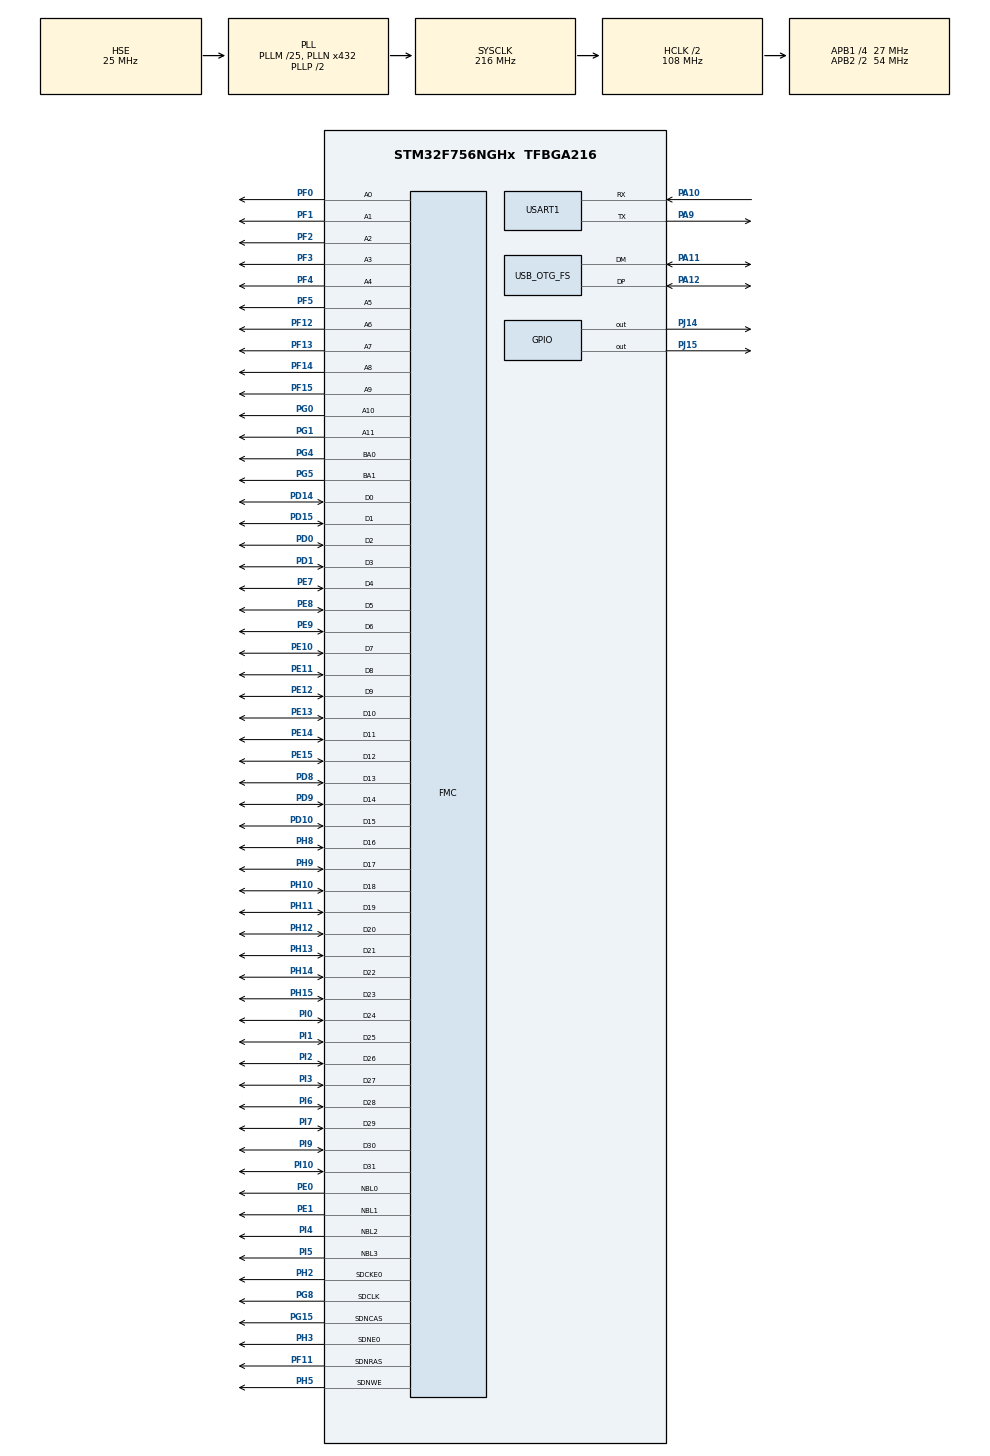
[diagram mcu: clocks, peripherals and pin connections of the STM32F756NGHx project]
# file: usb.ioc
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FMC.CASLatency1=FMC_SDRAM_CAS_LATENCY_3
FMC.ExitSelfRefreshDelay1=10
FMC.LoadToActiveDelay1=2
FMC.RCDDelay1=3
FMC.RPDelay1=3
FMC.RPDelay2=3
FMC.ReadBurst1=FMC_SDRAM_RBURST_ENABLE
FMC.ReadBurst2=FMC_SDRAM_RBURST_ENABLE
FMC.RowBitsNumber1=FMC_SDRAM_ROW_BITS_NUM_12
FMC.RowCycleDelay1=8
FMC.RowCycleDelay2=8
FMC.SDClockPeriod1=FMC_SDRAM_CLOCK_PERIOD_2
FMC.SDClockPeriod2=FMC_SDRAM_CLOCK_PERIOD_2
FMC.SelfRefreshTime1=4
FMC.WriteRecoveryTime1=2
Mcu.Family=STM32F7
Mcu.Name=STM32F756NGHx
Mcu.Package=TFBGA216
NVIC.OTG_FS_IRQn=true\:0\:0\:false\:false\:true
NVIC.PriorityGroup=NVIC_PRIORITYGROUP_4
PA10.Mode=Asynchronous
PA10.Signal=USART1_RX
PA11.Mode=Device_Only
PA11.Signal=USB_OTG_FS_DM
PA12.Mode=Device_Only
PA12.Signal=USB_OTG_FS_DP
PA9.Mode=Asynchronous
PA9.Signal=USART1_TX
PD0.Signal=FMC_D2_DA2
PD1.Signal=FMC_D3_DA3
PD10.Signal=FMC_D15_DA15
PD14.Signal=FMC_D0_DA0
PD15.Signal=FMC_D1_DA1
PD8.Signal=FMC_D13_DA13
PD9.Signal=FMC_D14_DA14
PE0.Signal=FMC_NBL0
PE1.Signal=FMC_NBL1
PE10.Signal=FMC_D7_DA7
PE11.Signal=FMC_D8_DA8
PE12.Signal=FMC_D9_DA9
PE13.Signal=FMC_D10_DA10
PE14.Signal=FMC_D11_DA11
PE15.Signal=FMC_D12_DA12
PE7.Signal=FMC_D4_DA4
PE8.Signal=FMC_D5_DA5
PE9.Signal=FMC_D6_DA6
PF0.Signal=FMC_A0
PF1.Signal=FMC_A1
PF11.Signal=FMC_SDNRAS
PF12.Signal=FMC_A6
PF13.Signal=FMC_A7
PF14.Signal=FMC_A8
PF15.Signal=FMC_A9
PF2.Signal=FMC_A2
PF3.Signal=FMC_A3
PF4.Signal=FMC_A4
PF5.Signal=FMC_A5
PG0.Signal=FMC_A10
PG1.Signal=FMC_A11
PG15.Signal=FMC_SDNCAS
PG4.Signal=FMC_A14_BA0
PG5.Signal=FMC_A15_BA1
PG8.Signal=FMC_SDCLK
PH0/OSC_IN.Mode=HSE-External-Oscillator
PH0/OSC_IN.Signal=RCC_OSC_IN
PH1/OSC_OUT.Mode=HSE-External-Oscillator
PH1/OSC_OUT.Signal=RCC_OSC_OUT
PH10.Signal=FMC_D18
PH11.Signal=FMC_D19
PH12.Signal=FMC_D20
PH13.Signal=FMC_D21
PH14.Signal=FMC_D22
PH15.Signal=FMC_D23
PH2.Mode=SdramChipSelect1_1
PH2.Signal=FMC_SDCKE0
PH3.Mode=SdramChipSelect1_1
PH3.Signal=FMC_SDNE0
PH5.Signal=FMC_SDNWE
PH8.Signal=FMC_D16
PH9.Signal=FMC_D17
PI0.Signal=FMC_D24
PI1.Signal=FMC_D25
PI10.Signal=FMC_D31
PI2.Signal=FMC_D26
PI3.Signal=FMC_D27
PI4.Signal=FMC_NBL2
PI5.Signal=FMC_NBL3
PI6.Signal=FMC_D28
PI7.Signal=FMC_D29
PI9.Signal=FMC_D30
PJ14.Signal=GPIO_Output
PJ15.Signal=GPIO_Output
ProjectManager.HeapSize=0x200
ProjectManager.StackSize=0x400
ProjectManager.TargetToolchain=SW4STM32
RCC.AHBCLKDivider=RCC_SYSCLK_DIV2
RCC.AHBFreq_Value=108000000
RCC.APB1CLKDivider=RCC_HCLK_DIV4
RCC.APB1Freq_Value=27000000
RCC.APB1TimFreq_Value=54000000
RCC.APB2CLKDivider=RCC_HCLK_DIV2
RCC.APB2Freq_Value=54000000
RCC.APB2TimFreq_Value=108000000
RCC.CortexFreq_Value=108000000
RCC.HCLKFreq_Value=108000000
RCC.HSE_VALUE=25000000
RCC.HSI_VALUE=16000000
RCC.LSE_VALUE=32768
RCC.PLLM=25
RCC.PLLN=432
RCC.PLLQ=9
RCC.SYSCLKFreq_VALUE=216000000
RCC.SYSCLKSource=RCC_SYSCLKSOURCE_PLLCLK
RCC.USART1CLockSelection=RCC_USART1CLKSOURCE_SYSCLK
RCC.USBFreq_Value=48000000
RCC.VCOOutputFreq_Value=432000000
SH.FMC_A0.0=FMC_A0,12b-sda1
SH.FMC_A1.0=FMC_A1,12b-sda1
SH.FMC_A10.0=FMC_A10,12b-sda1
SH.FMC_A11.0=FMC_A11,12b-sda1
SH.FMC_A14_BA0.0=FMC_BA0,FourSdramBanks1
SH.FMC_A15_BA1.0=FMC_BA1,FourSdramBanks1
SH.FMC_A2.0=FMC_A2,12b-sda1
SH.FMC_A3.0=FMC_A3,12b-sda1
SH.FMC_A4.0=FMC_A4,12b-sda1
SH.FMC_A5.0=FMC_A5,12b-sda1
SH.FMC_A6.0=FMC_A6,12b-sda1
SH.FMC_A7.0=FMC_A7,12b-sda1
SH.FMC_A8.0=FMC_A8,12b-sda1
SH.FMC_A9.0=FMC_A9,12b-sda1
SH.FMC_D0_DA0.0=FMC_D0,sd-32b-d1
SH.FMC_D10_DA10.0=FMC_D10,sd-32b-d1
SH.FMC_D11_DA11.0=FMC_D11,sd-32b-d1
SH.FMC_D12_DA12.0=FMC_D12,sd-32b-d1
SH.FMC_D13_DA13.0=FMC_D13,sd-32b-d1
SH.FMC_D14_DA14.0=FMC_D14,sd-32b-d1
SH.FMC_D15_DA15.0=FMC_D15,sd-32b-d1
SH.FMC_D16.0=FMC_D16,sd-32b-d1
SH.FMC_D17.0=FMC_D17,sd-32b-d1
SH.FMC_D18.0=FMC_D18,sd-32b-d1
SH.FMC_D19.0=FMC_D19,sd-32b-d1
SH.FMC_D1_DA1.0=FMC_D1,sd-32b-d1
SH.FMC_D20.0=FMC_D20,sd-32b-d1
SH.FMC_D21.0=FMC_D21,sd-32b-d1
SH.FMC_D22.0=FMC_D22,sd-32b-d1
SH.FMC_D23.0=FMC_D23,sd-32b-d1
SH.FMC_D24.0=FMC_D24,sd-32b-d1
SH.FMC_D25.0=FMC_D25,sd-32b-d1
SH.FMC_D26.0=FMC_D26,sd-32b-d1
SH.FMC_D27.0=FMC_D27,sd-32b-d1
SH.FMC_D28.0=FMC_D28,sd-32b-d1
SH.FMC_D29.0=FMC_D29,sd-32b-d1
SH.FMC_D2_DA2.0=FMC_D2,sd-32b-d1
SH.FMC_D30.0=FMC_D30,sd-32b-d1
SH.FMC_D31.0=FMC_D31,sd-32b-d1
SH.FMC_D3_DA3.0=FMC_D3,sd-32b-d1
SH.FMC_D4_DA4.0=FMC_D4,sd-32b-d1
SH.FMC_D5_DA5.0=FMC_D5,sd-32b-d1
SH.FMC_D6_DA6.0=FMC_D6,sd-32b-d1
SH.FMC_D7_DA7.0=FMC_D7,sd-32b-d1
SH.FMC_D8_DA8.0=FMC_D8,sd-32b-d1
SH.FMC_D9_DA9.0=FMC_D9,sd-32b-d1
SH.FMC_NBL0.0=FMC_NBL0,Sd4ByteEnable1
SH.FMC_NBL1.0=FMC_NBL1,Sd4ByteEnable1
SH.FMC_NBL2.0=FMC_NBL2,Sd4ByteEnable1
SH.FMC_NBL3.0=FMC_NBL3,Sd4ByteEnable1
SH.FMC_SDCLK.0=FMC_SDCLK,12b-sda1
SH.FMC_SDNCAS.0=FMC_SDNCAS,12b-sda1
SH.FMC_SDNRAS.0=FMC_SDNRAS,12b-sda1
SH.FMC_SDNWE.0=FMC_SDNWE,12b-sda1
USART1.WordLength=UART_WORDLENGTH_9B
USB_DEVICE.CLASS_NAME-DFU_FS=DFU
USB_DEVICE.USBD_HandleTypeDef-DFU_FS=hUsbDeviceFS
USB_DEVICE.VirtualMode-DFU_FS=Dfu
USB_DEVICE.VirtualModeFS=Dfu_FS
USB_OTG_FS.VirtualMode=Device_Only
VP_RNG_VS_RNG.Mode=RNG_Activate
VP_RTC_VS_RTC_Alarm_A_Intern.Mode=Alarm A
VP_RTC_VS_RTC_WakeUp_intern.Mode=WakeUp
VP_USB_DEVICE_VS_USB_DEVICE_DFU_FS.Mode=DFU_FS
board=usb

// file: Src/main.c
/**
  ******************************************************************************
  * File Name          : main.c
  * Description        : Main program body
  ******************************************************************************
  *
  * COPYRIGHT(c) 2016 STMicroelectronics
  *
  * Redistribution and use in source and binary forms, with or without modification,
  * are permitted provided that the following conditions are met:
  *   1. Redistributions of source code must retain the above copyright notice,
  *      this list of conditions and the following disclaimer.
  *   2. Redistributions in binary form must reproduce the above copyright notice,
  *      this list of conditions and the following disclaimer in the documentation
  *      and/or other materials provided with the distribution.
  *   3. Neither the name of STMicroelectronics nor the names of its contributors
  *      may be used to endorse or promote products derived from this software
  *      without specific prior written permission.
  *
  * THIS SOFTWARE IS PROVIDED BY THE COPYRIGHT HOLDERS AND CONTRIBUTORS "AS IS"
  * AND ANY EXPRESS OR IMPLIED WARRANTIES, INCLUDING, BUT NOT LIMITED TO, THE
  * IMPLIED WARRANTIES OF MERCHANTABILITY AND FITNESS FOR A PARTICULAR PURPOSE ARE
  * DISCLAIMED. IN NO EVENT SHALL THE COPYRIGHT HOLDER OR CONTRIBUTORS BE LIABLE
  * FOR ANY DIRECT, INDIRECT, INCIDENTAL, SPECIAL, EXEMPLARY, OR CONSEQUENTIAL
  * DAMAGES (INCLUDING, BUT NOT LIMITED TO, PROCUREMENT OF SUBSTITUTE GOODS OR
  * SERVICES; LOSS OF USE, DATA, OR PROFITS; OR BUSINESS INTERRUPTION) HOWEVER
  * CAUSED AND ON ANY THEORY OF LIABILITY, WHETHER IN CONTRACT, STRICT LIABILITY,
  * OR TORT (INCLUDING NEGLIGENCE OR OTHERWISE) ARISING IN ANY WAY OUT OF THE USE
  * OF THIS SOFTWARE, EVEN IF ADVISED OF THE POSSIBILITY OF SUCH DAMAGE.
  *
  ******************************************************************************
  */
#include "stm32f7xx_hal.h"
#include "usb_device.h"
#include "stdio.h"

//#include "stm32f756xx.h"
#define SysTick_IRQn  (-1)

RNG_HandleTypeDef hrng;

RTC_HandleTypeDef hrtc;

UART_HandleTypeDef huart1;

SDRAM_HandleTypeDef hsdram1;

/* USER CODE BEGIN PV */
/* Private variables ---------------------------------------------------------*/
#ifdef __GNUC__
/* With GCC/RAISONANCE, small printf (option LD Linker->Libraries->Small printf
   set to 'Yes') calls __io_putchar() */
#define PUTCHAR_PROTOTYPE int __io_putchar(int ch)
#else
#define PUTCHAR_PROTOTYPE int fputc(int ch, FILE *f)
#endif /* __GNUC__ */
/**
  * @brief  Retargets the C library printf function to the USART.
  * @param  None
  * @retval None
  */
PUTCHAR_PROTOTYPE
{
  /* Place your implementation of fputc here */
  /* e.g. write a character to the EVAL_COM1 and Loop until the end of transmission */
  HAL_UART_Transmit(&huart1, (uint8_t *)&ch, 1, 0xFFFF);

  return ch;
}

/* USER CODE END PV */

void SystemClock_Config(void);
void Error_Handler(void);
static void CPU_CACHE_Enable(void);
static void MX_GPIO_Init(void);
static void MX_USART1_UART_Init(void);
static void MX_FMC_Init(void);
static void MX_RNG_Init(void);
static void MX_RTC_Init(void);

/* USER CODE BEGIN PFP */
/* Private function prototypes -----------------------------------------------*/

/* USER CODE END PFP */

/* USER CODE BEGIN 0 */
typedef  void (*pFunction)(void);
pFunction JumpToApplication;
uint32_t JumpAddress;
/* USER CODE END 0 */

int main(void)
{
  /* USER CODE BEGIN 1 */
  /* Enable the CPU Cache */
  CPU_CACHE_Enable();
  /* USER CODE END 1 */

  /* MCU Configuration----------------------------------------------------------*/

  /* Reset of all peripherals, Initializes the Flash interface and the Systick. */
  HAL_Init();

  /* Configure the system clock */
  SystemClock_Config();

  /* Initialize all configured peripherals */
  MX_GPIO_Init();
  MX_USART1_UART_Init();
  MX_FMC_Init();
  MX_RNG_Init();
  MX_RTC_Init();

  printf("\n\rNIU Eye Bootloader V0.1\n\r");

  GPIO_PinState forceload;
  forceload = HAL_GPIO_ReadPin(GPIOJ, GPIO_PIN_0);
  printf("B2 input %d\n\r", forceload);

  if(!forceload)
  {
	  //printf("*(0x%08x) = 0x%08x\n\r", USBD_DFU_APP_DEFAULT_ADD, *(__IO uint32_t*)USBD_DFU_APP_DEFAULT_ADD);
	  /* Test if user code is programmed starting from USBD_DFU_APP_DEFAULT_ADD address */
	  //if(((*(__IO uint32_t*)USBD_DFU_APP_DEFAULT_ADD) & 0x2FFE0000 ) == 0x20000000)
	  if((*(__IO uint32_t*)USBD_DFU_APP_DEFAULT_ADD ) == 0x20050000)
	  {
		/* Jump to user application */
		JumpAddress = *(__IO uint32_t*) (USBD_DFU_APP_DEFAULT_ADD + 4);
		JumpToApplication = (pFunction) JumpAddress;

		printf("find APP at 0x%08x, start function 0x%08x\n\r", USBD_DFU_APP_DEFAULT_ADD, JumpAddress);
		/* Initialize user application's Stack Pointer */
		__set_MSP(*(__IO uint32_t*) USBD_DFU_APP_DEFAULT_ADD);
		JumpToApplication();
	  }
	  printf("Not find APP at 0x%08x, start DFU mode\n\r", USBD_DFU_APP_DEFAULT_ADD);
  }
  else
  {
	  printf("Force download new firmware !!!\n\r");
  }

  MX_USB_DEVICE_Init();

  /* Infinite loop */
  while (1)
  {

  }

}

/** System Clock Configuration
*/
void SystemClock_Config(void)
{

  RCC_OscInitTypeDef RCC_OscInitStruct;
  RCC_ClkInitTypeDef RCC_ClkInitStruct;
  RCC_PeriphCLKInitTypeDef PeriphClkInitStruct;

  __HAL_RCC_PWR_CLK_ENABLE();

  __HAL_PWR_VOLTAGESCALING_CONFIG(PWR_REGULATOR_VOLTAGE_SCALE3);

  RCC_OscInitStruct.OscillatorType = RCC_OSCILLATORTYPE_LSI|RCC_OSCILLATORTYPE_HSE;
  RCC_OscInitStruct.HSEState = RCC_HSE_ON;
  RCC_OscInitStruct.LSIState = RCC_LSI_ON;
  RCC_OscInitStruct.PLL.PLLState = RCC_PLL_ON;
  RCC_OscInitStruct.PLL.PLLSource = RCC_PLLSOURCE_HSE;
  RCC_OscInitStruct.PLL.PLLM = 25;
  RCC_OscInitStruct.PLL.PLLN = 432;
  RCC_OscInitStruct.PLL.PLLP = RCC_PLLP_DIV2;
  RCC_OscInitStruct.PLL.PLLQ = 9;
  if (HAL_RCC_OscConfig(&RCC_OscInitStruct) != HAL_OK)
  {
    Error_Handler();
  }

  RCC_ClkInitStruct.ClockType = RCC_CLOCKTYPE_HCLK|RCC_CLOCKTYPE_SYSCLK
                              |RCC_CLOCKTYPE_PCLK1|RCC_CLOCKTYPE_PCLK2;
  RCC_ClkInitStruct.SYSCLKSource = RCC_SYSCLKSOURCE_PLLCLK;
  RCC_ClkInitStruct.AHBCLKDivider = RCC_SYSCLK_DIV2;
  RCC_ClkInitStruct.APB1CLKDivider = RCC_HCLK_DIV4;
  RCC_ClkInitStruct.APB2CLKDivider = RCC_HCLK_DIV2;
  if (HAL_RCC_ClockConfig(&RCC_ClkInitStruct, FLASH_LATENCY_3) != HAL_OK)
  {
    Error_Handler();
  }

  PeriphClkInitStruct.PeriphClockSelection = RCC_PERIPHCLK_RTC|RCC_PERIPHCLK_USART1
                              |RCC_PERIPHCLK_CLK48;
  PeriphClkInitStruct.RTCClockSelection = RCC_RTCCLKSOURCE_LSI;
  PeriphClkInitStruct.Usart1ClockSelection = RCC_USART1CLKSOURCE_SYSCLK;
  PeriphClkInitStruct.Clk48ClockSelection = RCC_CLK48SOURCE_PLL;
  if (HAL_RCCEx_PeriphCLKConfig(&PeriphClkInitStruct) != HAL_OK)
  {
    Error_Handler();
  }

  HAL_SYSTICK_Config(HAL_RCC_GetHCLKFreq()/1000);

  HAL_SYSTICK_CLKSourceConfig(SYSTICK_CLKSOURCE_HCLK);

  /* SysTick_IRQn interrupt configuration */
  HAL_NVIC_SetPriority(SysTick_IRQn, 0, 0);
}

/* RNG init function */
static void MX_RNG_Init(void)
{

  hrng.Instance = RNG;
  if (HAL_RNG_Init(&hrng) != HAL_OK)
  {
    Error_Handler();
  }

}

/* RTC init function */
static void MX_RTC_Init(void)
{

  RTC_TimeTypeDef sTime;
  RTC_DateTypeDef sDate;
  RTC_AlarmTypeDef sAlarm;

    /**Initialize RTC and set the Time and Date
    */
  hrtc.Instance = RTC;
  hrtc.Init.HourFormat = RTC_HOURFORMAT_24;
  hrtc.Init.AsynchPrediv = 127;
  hrtc.Init.SynchPrediv = 255;
  hrtc.Init.OutPut = RTC_OUTPUT_DISABLE;
  hrtc.Init.OutPutPolarity = RTC_OUTPUT_POLARITY_HIGH;
  hrtc.Init.OutPutType = RTC_OUTPUT_TYPE_OPENDRAIN;
  if (HAL_RTC_Init(&hrtc) != HAL_OK)
  {
    Error_Handler();
  }

  sTime.Hours = 0x0;
  sTime.Minutes = 0x0;
  sTime.Seconds = 0x0;
  sTime.DayLightSaving = RTC_DAYLIGHTSAVING_NONE;
  sTime.StoreOperation = RTC_STOREOPERATION_RESET;
  if (HAL_RTC_SetTime(&hrtc, &sTime, RTC_FORMAT_BCD) != HAL_OK)
  {
    Error_Handler();
  }

  sDate.WeekDay = RTC_WEEKDAY_MONDAY;
  sDate.Month = RTC_MONTH_JANUARY;
  sDate.Date = 0x1;
  sDate.Year = 0x0;

  if (HAL_RTC_SetDate(&hrtc, &sDate, RTC_FORMAT_BCD) != HAL_OK)
  {
    Error_Handler();
  }

    /**Enable the Alarm A
    */
  sAlarm.AlarmTime.Hours = 0x0;
  sAlarm.AlarmTime.Minutes = 0x0;
  sAlarm.AlarmTime.Seconds = 0x0;
  sAlarm.AlarmTime.SubSeconds = 0x0;
  sAlarm.AlarmTime.DayLightSaving = RTC_DAYLIGHTSAVING_NONE;
  sAlarm.AlarmTime.StoreOperation = RTC_STOREOPERATION_RESET;
  sAlarm.AlarmMask = RTC_ALARMMASK_NONE;
  sAlarm.AlarmSubSecondMask = RTC_ALARMSUBSECONDMASK_ALL;
  sAlarm.AlarmDateWeekDaySel = RTC_ALARMDATEWEEKDAYSEL_DATE;
  sAlarm.AlarmDateWeekDay = 0x1;
  sAlarm.Alarm = RTC_ALARM_A;
  if (HAL_RTC_SetAlarm(&hrtc, &sAlarm, RTC_FORMAT_BCD) != HAL_OK)
  {
    Error_Handler();
  }

    /**Enable the WakeUp
    */
  if (HAL_RTCEx_SetWakeUpTimer(&hrtc, 0, RTC_WAKEUPCLOCK_RTCCLK_DIV16) != HAL_OK)
  {
    Error_Handler();
  }

}

/* USART1 init function */
static void MX_USART1_UART_Init(void)
{

  huart1.Instance = USART1;
  huart1.Init.BaudRate = 115200;
  huart1.Init.WordLength = UART_WORDLENGTH_9B;
  huart1.Init.StopBits = UART_STOPBITS_1;
  huart1.Init.Parity = UART_PARITY_NONE;
  huart1.Init.Mode = UART_MODE_TX_RX;
  huart1.Init.HwFlowCtl = UART_HWCONTROL_NONE;
  huart1.Init.OverSampling = UART_OVERSAMPLING_16;
  huart1.Init.OneBitSampling = UART_ONE_BIT_SAMPLE_DISABLE;
  huart1.AdvancedInit.AdvFeatureInit = UART_ADVFEATURE_NO_INIT;
  if (HAL_UART_Init(&huart1) != HAL_OK)
  {
    Error_Handler();
  }

}
/* FMC initialization function */
static void MX_FMC_Init(void)
{
  FMC_SDRAM_TimingTypeDef SdramTiming;

  /** Perform the SDRAM1 memory initialization sequence
  */
  hsdram1.Instance = FMC_SDRAM_DEVICE;
  /* hsdram1.Init */
  hsdram1.Init.SDBank = FMC_SDRAM_BANK1;
  hsdram1.Init.ColumnBitsNumber = FMC_SDRAM_COLUMN_BITS_NUM_8;
  hsdram1.Init.RowBitsNumber = FMC_SDRAM_ROW_BITS_NUM_12;
  hsdram1.Init.MemoryDataWidth = FMC_SDRAM_MEM_BUS_WIDTH_32;
  hsdram1.Init.InternalBankNumber = FMC_SDRAM_INTERN_BANKS_NUM_4;
  hsdram1.Init.CASLatency = FMC_SDRAM_CAS_LATENCY_3;
  hsdram1.Init.WriteProtection = FMC_SDRAM_WRITE_PROTECTION_DISABLE;
  hsdram1.Init.SDClockPeriod = FMC_SDRAM_CLOCK_PERIOD_2;
  hsdram1.Init.ReadBurst = FMC_SDRAM_RBURST_ENABLE;
  hsdram1.Init.ReadPipeDelay = FMC_SDRAM_RPIPE_DELAY_0;
  /* SdramTiming */
  SdramTiming.LoadToActiveDelay = 2;
  SdramTiming.ExitSelfRefreshDelay = 10;
  SdramTiming.SelfRefreshTime = 4;
  SdramTiming.RowCycleDelay = 8;
  SdramTiming.WriteRecoveryTime = 2;
  SdramTiming.RPDelay = 3;
  SdramTiming.RCDDelay = 3;

  if (HAL_SDRAM_Init(&hsdram1, &SdramTiming) != HAL_OK)
  {
    Error_Handler();
  }

}

/** Configure pins as
        * Analog
        * Input
        * Output
        * EVENT_OUT
        * EXTI
*/
static void MX_GPIO_Init(void)
{

  GPIO_InitTypeDef GPIO_InitStruct;

  /* GPIO Ports Clock Enable */
  __HAL_RCC_GPIOE_CLK_ENABLE();
  __HAL_RCC_GPIOG_CLK_ENABLE();
  __HAL_RCC_GPIOD_CLK_ENABLE();
  __HAL_RCC_GPIOA_CLK_ENABLE();
  __HAL_RCC_GPIOI_CLK_ENABLE();
  __HAL_RCC_GPIOJ_CLK_ENABLE();
  __HAL_RCC_GPIOF_CLK_ENABLE();
  __HAL_RCC_GPIOH_CLK_ENABLE();

  /*Configure GPIO pin Output Level */
  HAL_GPIO_WritePin(GPIOJ, GPIO_PIN_14|GPIO_PIN_15, GPIO_PIN_RESET);

  /*Configure GPIO pins : PJ14 PJ15 */
  GPIO_InitStruct.Pin = GPIO_PIN_14|GPIO_PIN_15;
  GPIO_InitStruct.Mode = GPIO_MODE_OUTPUT_PP;
  GPIO_InitStruct.Pull = GPIO_NOPULL;
  GPIO_InitStruct.Speed = GPIO_SPEED_FREQ_LOW;
  HAL_GPIO_Init(GPIOJ, &GPIO_InitStruct);

  /*Configure GPIO pin : PJ0 */
  GPIO_InitStruct.Pin = GPIO_PIN_0;
  GPIO_InitStruct.Mode = GPIO_MODE_INPUT;
  GPIO_InitStruct.Pull = GPIO_NOPULL;
  HAL_GPIO_Init(GPIOJ, &GPIO_InitStruct);

}

/**
  * @brief  CPU L1-Cache enable.
  * @param  None
  * @retval None
  */
static void CPU_CACHE_Enable(void)
{
  /* Enable I-Cache */
  SCB_EnableICache();

  /* Enable D-Cache */
  SCB_EnableDCache();
}

void Error_Handler(void)
{
  /* USER CODE BEGIN Error_Handler */
  /* User can add his own implementation to report the HAL error return state */
  while(1)
  {
  	printf("Error_Handler !!!\n\r");
  }
  /* USER CODE END Error_Handler */
}

/************************ (C) COPYRIGHT STMicroelectronics *****END OF FILE****/
